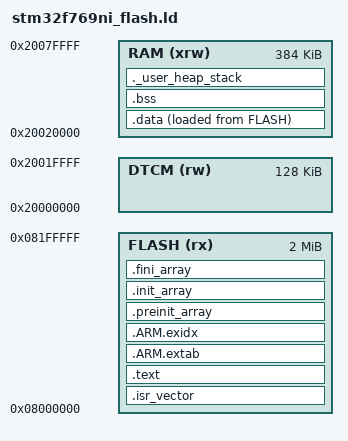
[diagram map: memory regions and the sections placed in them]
/* STM32F769NI flash linker script for the CWIST bare-metal demo.
 * Everything (data, bss, heap, lwIP pools, ETH DMA buffers) lives in
 * SRAM1+SRAM2 at 0x20020000 so the Ethernet DMA can reach all of it;
 * the DTCM at 0x20000000 is left to the stack (CPU-only anyway). */
ENTRY(Reset_Handler)

_estack = ORIGIN(RAM) + LENGTH(RAM); /* end of RAM: stack grows down */
_Min_Heap_Size = 0x10000;  /* 64 KB heap for CWIST + lwIP + newlib */
_Min_Stack_Size = 0x4000;  /* 16 KB main stack */

MEMORY
{
  FLASH (rx)  : ORIGIN = 0x08000000, LENGTH = 2048K
  DTCM  (rw)  : ORIGIN = 0x20000000, LENGTH = 128K
  RAM   (xrw) : ORIGIN = 0x20020000, LENGTH = 384K
}

SECTIONS
{
  .isr_vector : { . = ALIGN(4); KEEP(*(.isr_vector)) . = ALIGN(4); } >FLASH

  .text :
  {
    . = ALIGN(4);
    *(.text*) *(.rodata*)
    KEEP(*(.init)) KEEP(*(.fini))
    . = ALIGN(4);
    _etext = .;
  } >FLASH

  .ARM.extab : { *(.ARM.extab* .gnu.linkonce.armextab.*) } >FLASH
  .ARM.exidx : { __exidx_start = .; *(.ARM.exidx* .gnu.linkonce.armexidx.*) __exidx_end = .; } >FLASH

  .preinit_array :
  {
    PROVIDE_HIDDEN(__preinit_array_start = .);
    KEEP(*(.preinit_array*))
    PROVIDE_HIDDEN(__preinit_array_end = .);
  } >FLASH
  .init_array :
  {
    PROVIDE_HIDDEN(__init_array_start = .);
    KEEP(*(SORT(.init_array.*)))
    KEEP(*(.init_array*))
    PROVIDE_HIDDEN(__init_array_end = .);
  } >FLASH
  .fini_array :
  {
    PROVIDE_HIDDEN(__fini_array_start = .);
    KEEP(*(SORT(.fini_array.*)))
    KEEP(*(.fini_array*))
    PROVIDE_HIDDEN(__fini_array_end = .);
  } >FLASH

  _sidata = LOADADDR(.data);
  .data :
  {
    . = ALIGN(4);
    _sdata = .;
    *(.data*)
    . = ALIGN(4);
    _edata = .;
  } >RAM AT> FLASH

  .bss (NOLOAD) :
  {
    . = ALIGN(4);
    _sbss = .;
    *(.bss*)
    *(COMMON)
    . = ALIGN(4);
    _ebss = .;
  } >RAM

  ._user_heap_stack (NOLOAD) :
  {
    . = ALIGN(8);
    PROVIDE(end = .);
    PROVIDE(_end = .);
    . = . + _Min_Heap_Size;
    . = . + _Min_Stack_Size;
    . = ALIGN(8);
  } >RAM

  /DISCARD/ : { *(.ARM.attributes) }
}
